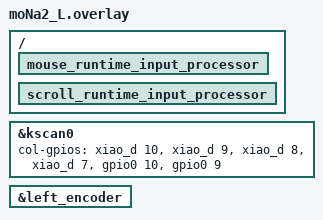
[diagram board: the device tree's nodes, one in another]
#include "moNa2.dtsi"
#include <behaviors/battery_history_request.dtsi>

&kscan0 {
        col-gpios
            = <&xiao_d 10 GPIO_ACTIVE_HIGH>
            , <&xiao_d 9 GPIO_ACTIVE_HIGH> 
            , <&xiao_d 8 GPIO_ACTIVE_HIGH> 
            , <&xiao_d 7 GPIO_ACTIVE_HIGH> 
            , <&gpio0 10 GPIO_ACTIVE_HIGH>
            , <&gpio0 9 GPIO_ACTIVE_HIGH>
            ;
};

&left_encoder {
    status = "okay";
};

/* Dummy nodes to resolve label references on the peripheral side */
/ {
    mouse_runtime_input_processor: mouse_runtime_input_processor {
        #input-processor-cells = <0>;
    };
    scroll_runtime_input_processor: scroll_runtime_input_processor {
        #input-processor-cells = <0>;
    };
};
